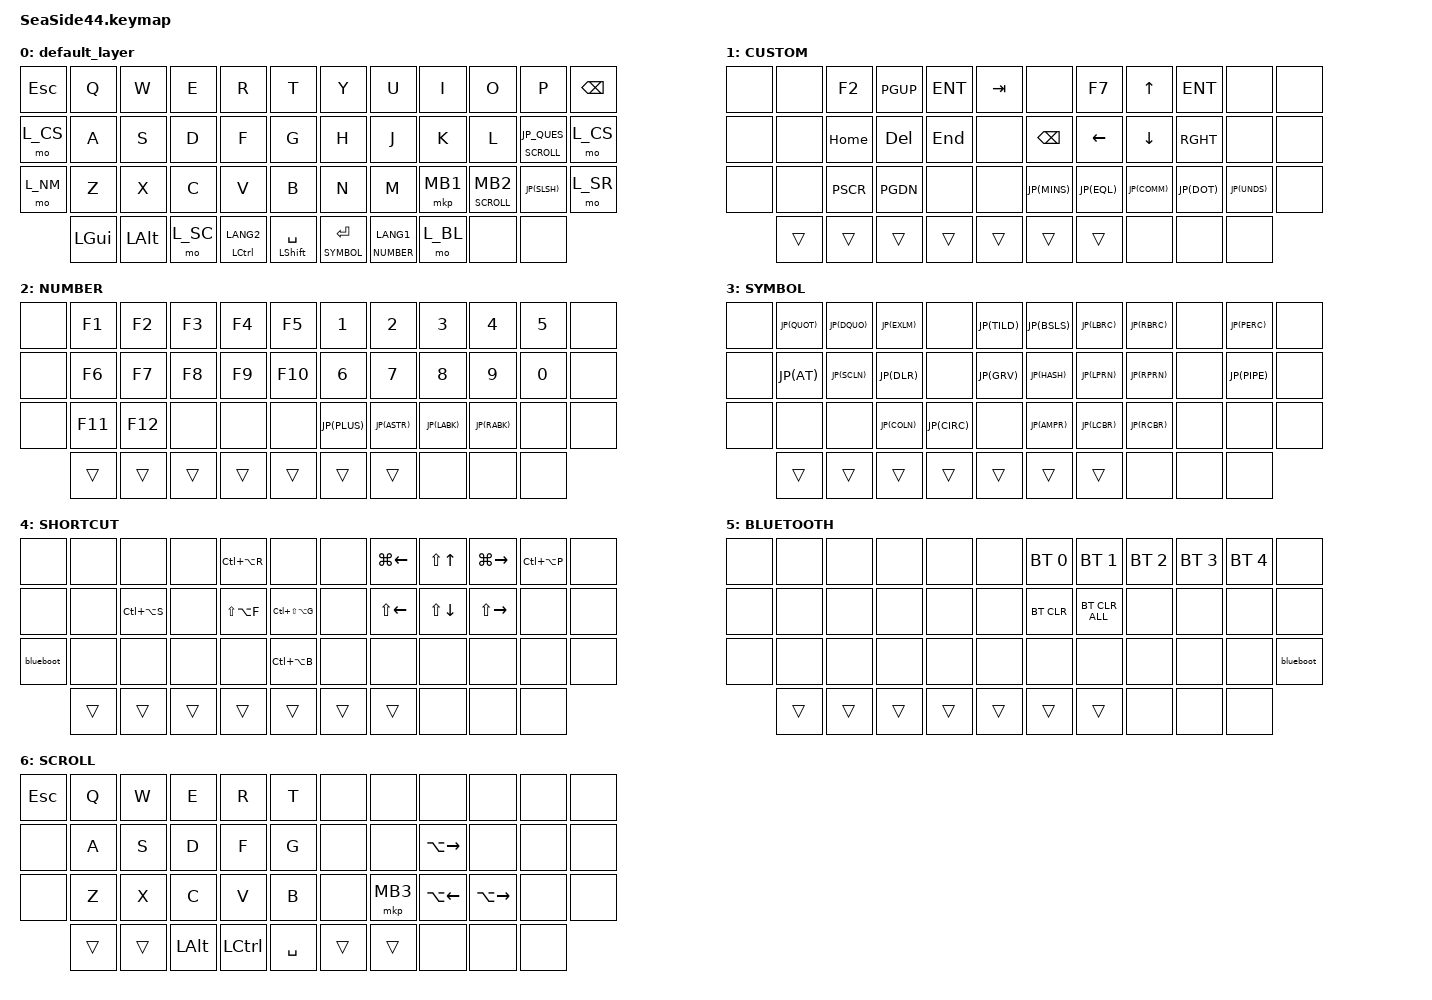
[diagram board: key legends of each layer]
#include <behaviors.dtsi>
#include <behaviors/blueboot.dtsi>
#include <dt-bindings/zmk/bt.h>
#include <dt-bindings/zmk/keys.h>
#include <dt-bindings/zmk/pointing.h>
#include "keymap_japanese.dtsi"

/* レイヤー番号に名前を定義（管理が圧倒的に楽になります） */
#define L_CS   1    // CUSTOM
#define L_NM   2    // NUMBER
#define L_SY   3    // SYMBOL
#define L_SC   4    // SHORTCUT
#define L_BL   5    // BLUETOOTH
#define L_SR   6    // SCROLL

#define CUSTOM   1    // CUSTOM
#define NUMBER   2    // NUMBER
#define SYMBOL   3    // SYMBOL
#define SHORTCUT   4    // SHORTCUT
#define BLUETOOTH   5    // BLUETOOTH
#define SCROLL   6    // SCROLL

&mt {
    flavor = "balanced";
    quick-tap-ms = <120>;
};

&lt {
    flavor = "balanced";
    quick-tap-ms = <120>;
};

/ {
    combos { compatible = "zmk,combos"; };

    macros {
        to_layer_0: to_layer_0 {
            compatible = "zmk,behavior-macro-one-param";
            #binding-cells = <1>;
            bindings = <&to 0 &macro_param_1to1 &kp MACRO_PLACEHOLDER>;
            label = "TO_LAYER_0";
        };

        number_layer_ime: number_layer_ime {
            compatible = "zmk,behavior-macro-one-param";
            #binding-cells = <1>;
            bindings = <&kp LANG2>,
                       <&macro_param_1to1>,
                       <&macro_press &mo MACRO_PLACEHOLDER>,
                       <&macro_pause_for_release>,
                       <&macro_param_1to1>,
                       <&macro_release &mo MACRO_PLACEHOLDER>,
                       <&macro_tap>,
                       <&kp LANG1>;
            label = "NUMBER_LAYER_IME";
        };
    };

    behaviors {
        lt_to_layer_0: lt_to_layer_0 {
            compatible = "zmk,behavior-hold-tap";
            label = "LAYER_TAP_TO_0";
            bindings = <&mo>, <&to_layer_0>;

            #binding-cells = <2>;
            tapping-term-ms = <120>;
        };

        lt_number_ime: lt_number_ime {
            compatible = "zmk,behavior-hold-tap";
            label = "LAYER_TAP_NUMBER_IME";
            bindings = <&number_layer_ime>, <&kp>;

            #binding-cells = <2>;
            flavor = "balanced";
            tapping-term-ms = <120>;
            quick-tap-ms = <120>;
        };

        mb2_layer: mb2_layer {
            compatible = "zmk,behavior-hold-tap";

            #binding-cells = <2>;
            bindings = <&mo>, <&mkp>;

            tapping-term-ms = <120>;
        };
    };


/* 矢印キーの短縮定義 */
#define UP     UP_ARROW
#define DOWN   DOWN_ARROW
#define LEFT   LEFT_ARROW
#define RGHT   RIGHT_ARROW

/* キー名・単語の短縮定義 */
#define ENT    ENTER
// #define ESC    ESCAPE
// #define SPC    SPACE
#define MINS   MINUS
// #define EQL    EQUAL
#define QUES   QUESTION
#define PSCR   PRINTSCREEN
// #define PGUP   PAGE_UP
// #define PGDN   PAGE_DOWN
#define COMM   COMMA
#define SLSH   SLASH
#define ASTR   ASTERISK
#define UNDS   UNDERSCORE
// #define TILD   TILDE
#define GRV    GRAVE
// #define COLN   COLON
#define CIRC   CARET
#define PERC   PERCENT

/* 複合キー・システムキーの短縮定義 */
#define CTL_LG2 &mt LCTRL LANG2        // ctrl 英字
#define SFT_SPC &mt LSHIFT SPACE       // shift space
#define LSY_ENT &lt SYMBOL ENTER            // レイヤ3 enter
#define LNM_LG1 &lt_number_ime NUMBER LANG1 // レイヤ2 英字（押下）/かな（解放）
#define LSC_QUE &lt SCROLL JP_QUES       // スクロール ?
#define LSR_MB2 &mb2_layer SCROLL MB2          // スクロール 右クリック
#define BITWAR  &kp LS(LA(F))          // shift alt f

#define RECORD  &kp LC(LA(R))          // ctrl alt r
#define SAVE    &kp LC(LA(S))          // ctrl alt s
#define PLAY   &kp LC(LA(P))          // ctrl alt p
#define PAUSE   &kp LC(LA(B))          // ctrl alt b
#define SENDENV  &kp LC(LS(LA(G)))     // ctrl shift alt g

#define LSUP    &kp LS(UP)             // shift 上
#define LSDOWN  &kp LS(DOWN)           // shift 下
#define LSLEFT  &kp LS(LEFT)           // shift 左
#define LSRIGHT &kp LS(RIGHT)          // shift 右
#define LGLEFT  &kp LG(LEFT)           // win 左
#define LGRIGHT &kp LG(RIGHT)          // win 右
#define LALEFT  &kp LA(LEFT)           // alt 左
#define LARIGHT &kp LA(RIGHT)          // alt 右
#define BOOT    &bootloader          // ブートローダー起動
#define BLEBOOT &blueboot           // BlueBoot 起動
#define BTS0    &bt BT_SEL 0         // 接続先0
#define BTS1    &bt BT_SEL 1         // 接続先1
#define BTS2    &bt BT_SEL 2         // 接続先2
#define BTS3    &bt BT_SEL 3         // 接続先3
#define BTS4    &bt BT_SEL 4         // 接続先4
#define BTC      &bt BT_CLR         // 接続先クリア
#define BTC_ALL    &bt BT_CLR_ALL    // すべての接続先をクリア

keymap {
        compatible = "zmk,keymap";

        default_layer {
            bindings = <
&kp ESC   &kp Q     &kp W     &kp E     &kp R     &kp T             &kp Y     &kp U     &kp I     &kp O     &kp P     &kp BSPC
&mo L_CS  &kp A     &kp S     &kp D     &kp F     &kp G             &kp H     &kp J     &kp K     &kp L     LSC_QUE   &mo L_CS
&mo L_NM  &kp Z     &kp X     &kp C     &kp V     &kp B             &kp N     &kp M     &mkp MB1  LSR_MB2   JP(SLSH)  &mo L_SR
          &kp LGUI  &kp LALT  &mo L_SC  CTL_LG2   SFT_SPC           LSY_ENT   LNM_LG1   &mo L_BL  &none     &none
            >;
        };

        CUSTOM {
            bindings = <
&none     &none     &kp F2    &kp PGUP  &kp ENT   &kp TAB           &none     &kp F7    &kp UP    &kp ENT   &none     &none
&none     &none     &kp HOME  &kp DEL   &kp END   &none             &kp BSPC  &kp LEFT  &kp DOWN  &kp RGHT  &none     &none
&none     &none     &kp PSCR  &kp PGDN  &none     &none             JP(MINS)  JP(EQL)   JP(COMM)  JP(DOT)   JP(UNDS)  &none
          &trans    &trans    &trans    &trans    &trans            &trans    &trans    &none     &none     &none
            >;
        };

        NUMBER {
            bindings = <
&none     &kp F1    &kp F2    &kp F3    &kp F4    &kp F5            &kp N1    &kp N2    &kp N3    &kp N4    &kp N5    &none
&none     &kp F6    &kp F7    &kp F8    &kp F9    &kp F10           &kp N6    &kp N7    &kp N8    &kp N9    &kp N0    &none
&none     &kp F11   &kp F12   &none     &none     &none             JP(PLUS)  JP(ASTR)  JP(LABK)  JP(RABK)  &none     &none
          &trans    &trans    &trans    &trans    &trans            &trans    &trans    &none     &none     &none
            >;
        };

        SYMBOL {
            bindings = <
&none     JP(QUOT)  JP(DQUO)  JP(EXLM)  &none     JP(TILD)          JP(BSLS)  JP(LBRC)  JP(RBRC)  &none     JP(PERC)  &none
&none     JP(AT)    JP(SCLN)  JP(DLR)   &none     JP(GRV)           JP(HASH)  JP(LPRN)  JP(RPRN)  &none     JP(PIPE)  &none
&none     &none     &none     JP(COLN)  JP(CIRC)  &none             JP(AMPR)  JP(LCBR)  JP(RCBR)  &none     &none     &none
          &trans    &trans    &trans    &trans    &trans            &trans    &trans    &none     &none     &none
            >;
        };

        SHORTCUT {
            bindings = <
&none     &none     &none     &none     RECORD    &none             &none     LGLEFT    LSUP      LGRIGHT   PLAY      &none
&none     &none     SAVE      &none     BITWAR    SENDENV           &none     LSLEFT    LSDOWN    LSRIGHT   &none     &none
BLEBOOT   &none     &none     &none     &none     PAUSE             &none     &none     &none     &none     &none     &none
          &trans    &trans    &trans    &trans    &trans            &trans    &trans    &none     &none     &none
            >;
        };

        BLUETOOTH {
            bindings = <
&none     &none     &none     &none     &none     &none             BTS0      BTS1      BTS2      BTS3      BTS4      &none
&none     &none     &none     &none     &none     &none             BTC       BTC_ALL   &none     &none     &none     &none
&none     &none     &none     &none     &none     &none             &none     &none     &none     &none     &none     BLEBOOT
          &trans    &trans    &trans    &trans    &trans            &trans    &trans    &none     &none     &none
            >;
        };

        SCROLL {
            bindings = <
&kp ESC   &kp Q     &kp W     &kp E     &kp R     &kp T             &none     &none     &none     &none     &none     &none
&none     &kp A     &kp S     &kp D     &kp F     &kp G             &none     &none     LARIGHT   &none     &none     &none
&none     &kp Z     &kp X     &kp C     &kp V     &kp B             &none     &mkp MB3  LALEFT    LARIGHT   &none     &none
            &trans   &trans   &kp LALT  &kp LCTL  &kp SPC           &trans    &trans    &none     &none     &none
            >;
        };

    };
};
